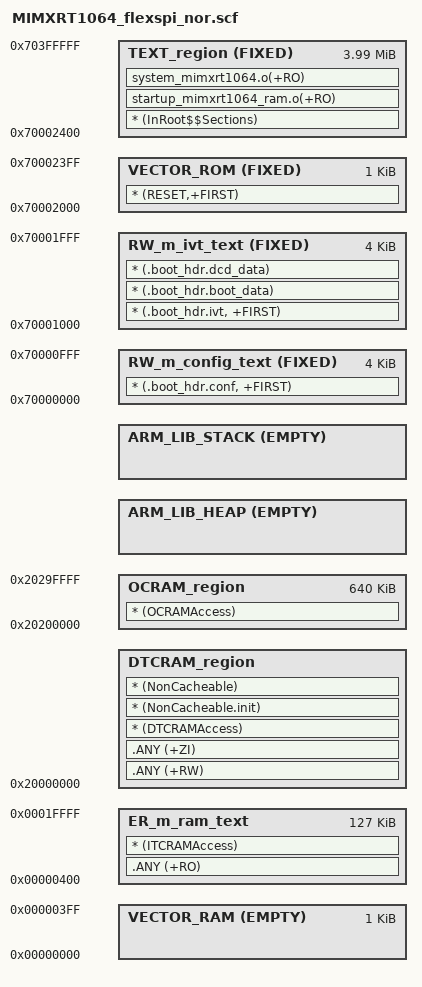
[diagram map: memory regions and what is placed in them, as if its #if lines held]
#! armcc -E
/*
** ###################################################################
**     Processors:          MIMXRT1052CVJ5B
**                          MIMXRT1052CVL5B
**                          MIMXRT1052DVJ6B
**                          MIMXRT1052DVL6B
**
**     Compiler:            Keil ARM C/C++ Compiler
**     Reference manual:    IMXRT1050RM Rev.1, 03/2018
**     Version:             rev. 1.0, 2018-09-21
**     Build:               b180921
**
**     Abstract:
**         Linker file for the Keil ARM C/C++ Compiler
**
**     Copyright 2016 Freescale Semiconductor, Inc.
**     Copyright 2016-2018 NXP
**     All rights reserved.
**
**     SPDX-License-Identifier: BSD-3-Clause
**
**     http:                 www.nxp.com
**     mail:                 support@nxp.com
**
** ###################################################################
*/
/* FLASH配置和ivt等信息 */
#define m_flash_config_start           0x70000000
#define m_flash_config_size            0x00001000

#define m_ivt_start                    0x70001000
#define m_ivt_size                     0x00001000

/* 中断向量表 */
#define m_interrupts_start             0x70002000
#define m_interrupts_size              0x00000400

/* ITCRAM 中断向量表 */
#define itcram_interrupts_start        0x00000000
#define itcram_interrupts_size         0x00000400

// 代码存放位置 
#define m_text_start                   0x70002400
#define m_text_size                    0x003FDC00

// DTCRAM 256K
#define dtcram_start                   0x20000000
#define dtcram_size                    0x00040000

// OCRAM 640K
#define ocram_start                    0x20200000
#define ocram_size                     0x000A0000

// itcram 128K 
#define itcram_start                   0x00000400
#define itcram_size                    0x0001FC00 


// 栈大小 局部变量
#if (defined(__stack_size__))
  #define Stack_Size                   __stack_size__
#else
  #define Stack_Size                   0x04000
#endif

// 堆大小 动态分配malloc分配的空间
#if (defined(__heap_size__))
  #define Heap_Size                    __heap_size__
#else
  #define Heap_Size                    0x08000
#endif

#if defined(XIP_BOOT_HEADER_ENABLE) && (XIP_BOOT_HEADER_ENABLE == 1)
LR_m_text m_flash_config_start m_text_start+m_text_size-m_flash_config_start {   ; load region size_region
  RW_m_config_text m_flash_config_start FIXED m_flash_config_size { ; load address = execution address
    * (.boot_hdr.conf, +FIRST)
  }

  RW_m_ivt_text m_ivt_start FIXED m_ivt_size { ; load address = execution address
    * (.boot_hdr.ivt, +FIRST)
    * (.boot_hdr.boot_data)
    * (.boot_hdr.dcd_data)
  }
#else
LR_m_text m_interrupts_start m_text_start+m_text_size-m_interrupts_start {   ; load region size_region
#endif
/* 中断向量表存放位置 */
  VECTOR_ROM m_interrupts_start FIXED m_interrupts_size { ; load address = execution address
    * (RESET,+FIRST)
  }
  
  /* 代码段存放位置 */
  TEXT_region m_text_start FIXED m_text_size { ; load address = execution address
    * (InRoot$$Sections)
    startup_mimxrt1064_ram.o(+RO)
	system_mimxrt1064.o(+RO)
  }
  
  /* ITCRAM 中断向量表 */
  VECTOR_RAM itcram_interrupts_start EMPTY itcram_interrupts_size { ;execution address

  }
  
  /* ITCRAM段 */
  ER_m_ram_text itcram_start itcram_size{ ; RW data
	.ANY (+RO)
	* (ITCRAMAccess)
  }
  
  /* DTCRAM段 */
  DTCRAM_region dtcram_start dtcram_size-Stack_Size{ ; RW data
    .ANY (+RW)
	.ANY (+ZI)
	* (DTCRAMAccess)
	* (NonCacheable.init)
    * (NonCacheable)
  } 
  
  /* OCRAM段 */
  OCRAM_region ocram_start ocram_size{ ; 
	* (OCRAMAccess)
  }
  
  /* 堆区域  */
  ARM_LIB_HEAP +0 EMPTY Heap_Size {    ; Heap region growing up
  }
  
  /* 栈区域 栈是向下生长的 */
  ARM_LIB_STACK dtcram_start+dtcram_size EMPTY -Stack_Size { ; Stack region growing down
  }
  
}
